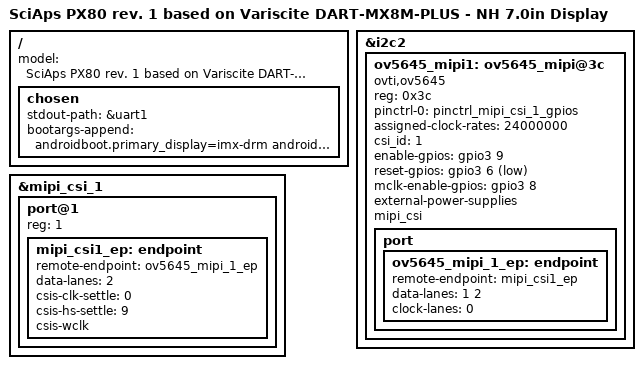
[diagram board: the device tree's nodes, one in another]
// SPDX-License-Identifier: (GPL-2.0+ OR MIT)
/*
 * Copyright 2019 NXP
 * Copyright 2020-2023 Variscite Ltd.
 * Copyright 2025 SciAps
 */

#include "imx8mp-var-dart-sciaps-btx.dtsi"

/ {
	model = "SciAps PX80 rev. 1 based on Variscite DART-MX8M-PLUS - NH 7.0in Display";
	chosen {
		stdout-path = &uart1;
		//console=ttymxc0,115200 earlycon=ec_imx6q,0x30860000,1/15200 androidboot.console=ttymxc0
		bootargs-append = "androidboot.primary_display=imx-drm androidboot.camera.layout=dual-ov5645 androidboot.sciaps.lcd_density=160 androidboot.sciaps.btx.model=PX80 moal.mod_para=wifi_mod_para_iw612.conf"; // wifi_mod_para_iw612.conf wifi_mod_para_sd8987.conf
	};
};

&i2c2 {
	ov5645_mipi1: ov5645_mipi@3c {
		compatible = "ovti,ov5645";
		reg = <0x3c>;
		pinctrl-names = "default";
		pinctrl-0 = <&pinctrl_mipi_csi_1_gpios>;
#if 0
		// Disabled as the board uses its own oscillator.
		clocks = <&clk IMX8MP_CLK_IPP_DO_CLKO2>;
		clock-names = "xclk";
		assigned-clocks = <&clk IMX8MP_CLK_IPP_DO_CLKO2>;
		assigned-clock-parents = <&clk IMX8MP_CLK_24M>;
		clock-frequency = <24000000>;
		mclk = <24000000>;
		mclk_source = <0>;
#endif
		assigned-clock-rates = <24000000>;
		csi_id = <1>;
		enable-gpios = <&gpio3 9 GPIO_ACTIVE_HIGH>;
		reset-gpios = <&gpio3 6 GPIO_ACTIVE_LOW>;
		mclk-enable-gpios = <&gpio3 8 GPIO_ACTIVE_HIGH>;
		external-power-supplies;
		mipi_csi;
		status = "okay";

		port {
			ov5645_mipi_1_ep: endpoint {
				remote-endpoint = <&mipi_csi1_ep>;
				data-lanes = <1 2>;
				clock-lanes = <0>;
			};
		};
	};
};

&mipi_csi_1 {
	#address-cells = <1>;
	#size-cells = <0>;
	status = "okay";

	port@1 {
		reg = <1>;
		mipi_csi1_ep: endpoint {
			remote-endpoint = <&ov5645_mipi_1_ep>;
			data-lanes = <2>;
			csis-clk-settle = <0>;
			csis-hs-settle = <9>;
			csis-wclk;
		};
	};
};

#include "imx8mp-android.dtsi"
